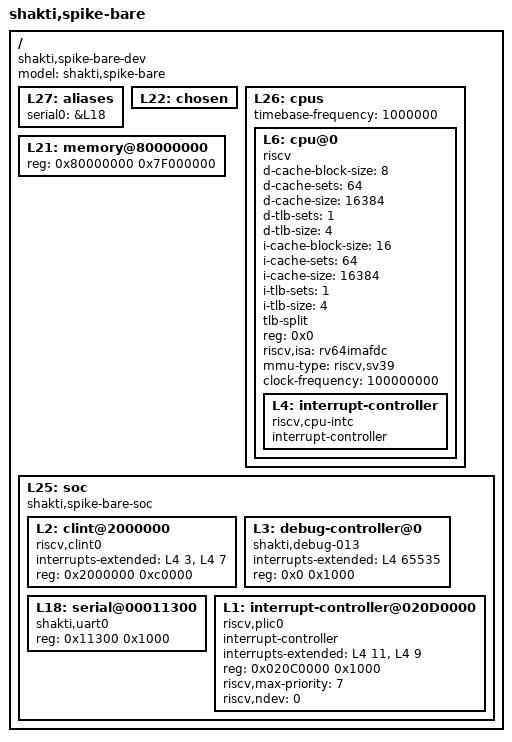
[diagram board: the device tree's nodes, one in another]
/dts-v1/;

/ {     
  	#address-cells = <1>;
  	#size-cells = <1>;
  	compatible = "shakti,spike-bare-dev";
  	model = "shakti,spike-bare";
	L27: aliases {
		serial0 = &L18;
	};
	L22: chosen {
	};
	L26: cpus {
		#address-cells = <1>;
		#size-cells = <0>;
		timebase-frequency = <1000000>;
		L6: cpu@0 {
			compatible = "riscv";
			d-cache-block-size = <8>;
			d-cache-sets = <64>;
			d-cache-size = <16384>;
			d-tlb-sets = <1>;
			d-tlb-size = <4>;
			device_type = "cpu";
			i-cache-block-size = <16>;
			i-cache-sets = <64>;
			i-cache-size = <16384>;
			i-tlb-sets = <1>;
			i-tlb-size = <4>;
			tlb-split;
			reg = <0x0>;
			status = "okay";
			riscv,isa = "rv64imafdc";
			mmu-type = "riscv,sv39";
			clock-frequency = <100000000>;					
			L4: interrupt-controller {
				#interrupt-cells = <1>;
				compatible = "riscv,cpu-intc";
				interrupt-controller;
			};		
		};
	};
	L21: memory@80000000 {
		device_type = "memory";
		reg = <0x80000000 0x7F000000>;
	};

	L25: soc {
		#address-cells = <1>;
		#size-cells = <1>;
		compatible = "shakti,spike-bare-soc", "simple-bus";
		ranges;
		L2: clint@2000000 {
			compatible = "riscv,clint0";
			interrupts-extended = <&L4 3 &L4 7 >;
			reg = <0x2000000 0xc0000>;
		};
		L3: debug-controller@0 {
			compatible = "shakti,debug-013", "riscv,debug-013";
			interrupts-extended = <&L4 65535>;
			reg = <0x0 0x1000>;
			reg-names = "control";
		};
		L18: serial@00011300 {
			compatible = "shakti,uart0";
			reg = <0x11300 0x1000>;
			reg-names = "control";
		};
		L1: interrupt-controller@020D0000 {
			#address-cells = <0>;
			#interrupt-cells = <1>;
			compatible = "riscv,plic0";
			interrupt-controller;
			interrupts-extended = <&L4 11 &L4 9>;
			reg = <0x020C0000 0x1000>;
			reg-names = "control";
			riscv,max-priority = <7>;
			riscv,ndev = <0>;
		};

	};
};
